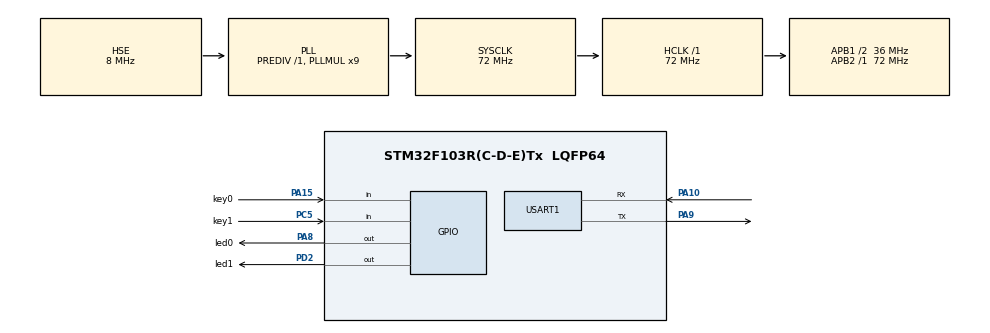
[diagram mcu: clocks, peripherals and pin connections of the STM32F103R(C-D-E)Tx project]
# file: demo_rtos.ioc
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Dma.Request0=USART1_RX
Dma.Request1=USART1_TX
Dma.USART1_RX.0.Direction=DMA_PERIPH_TO_MEMORY
Dma.USART1_RX.0.Instance=DMA1_Channel5
Dma.USART1_RX.0.MemDataAlignment=DMA_MDATAALIGN_BYTE
Dma.USART1_RX.0.MemInc=DMA_MINC_ENABLE
Dma.USART1_RX.0.Mode=DMA_NORMAL
Dma.USART1_RX.0.PeriphDataAlignment=DMA_PDATAALIGN_BYTE
Dma.USART1_RX.0.PeriphInc=DMA_PINC_DISABLE
Dma.USART1_RX.0.Priority=DMA_PRIORITY_LOW
Dma.USART1_TX.1.Direction=DMA_MEMORY_TO_PERIPH
Dma.USART1_TX.1.Instance=DMA1_Channel4
Dma.USART1_TX.1.MemDataAlignment=DMA_MDATAALIGN_BYTE
Dma.USART1_TX.1.MemInc=DMA_MINC_ENABLE
Dma.USART1_TX.1.Mode=DMA_NORMAL
Dma.USART1_TX.1.PeriphDataAlignment=DMA_PDATAALIGN_BYTE
Dma.USART1_TX.1.PeriphInc=DMA_PINC_DISABLE
Dma.USART1_TX.1.Priority=DMA_PRIORITY_LOW
FREERTOS.INCLUDE_eTaskGetState=0
FREERTOS.INCLUDE_uxTaskGetStackHighWaterMark=1
FREERTOS.INCLUDE_xQueueGetMutexHolder=1
FREERTOS.Tasks01=led0_on_and_off,24,128,led_task1,Default,NULL,Dynamic,NULL,NULL;led1taskk02,8,128,led_task2,Default,NULL,Dynamic,NULL,NULL
Mcu.Family=STM32F1
Mcu.Name=STM32F103R(C-D-E)Tx
Mcu.Package=LQFP64
NVIC.DMA1_Channel4_IRQn=true\:5\:0\:false\:false\:true\:true\:false\:true\:true
NVIC.DMA1_Channel5_IRQn=true\:5\:0\:false\:false\:true\:true\:false\:true\:true
NVIC.PriorityGroup=NVIC_PRIORITYGROUP_4
NVIC.TIM2_IRQn=true\:15\:0\:false\:false\:true\:false\:false\:true\:true
NVIC.TimeBase=TIM2_IRQn
NVIC.TimeBaseIP=TIM2
NVIC.USART1_IRQn=true\:5\:0\:true\:false\:true\:true\:true\:true\:true
PA10.Mode=Asynchronous
PA10.Signal=USART1_RX
PA13.Mode=Serial_Wire
PA13.Signal=SYS_JTMS-SWDIO
PA14.Mode=Serial_Wire
PA14.Signal=SYS_JTCK-SWCLK
PA15.GPIO_Label=key0
PA15.GPIO_PuPd=GPIO_NOPULL
PA15.Signal=GPIO_Input
PA8.GPIO_Label=led0
PA8.GPIO_PuPd=GPIO_PULLUP
PA8.GPIO_Speed=GPIO_SPEED_FREQ_MEDIUM
PA8.Signal=GPIO_Output
PA9.Mode=Asynchronous
PA9.Signal=USART1_TX
PC14-OSC32_IN.Mode=LSE-External-Oscillator
PC14-OSC32_IN.Signal=RCC_OSC32_IN
PC15-OSC32_OUT.Mode=LSE-External-Oscillator
PC15-OSC32_OUT.Signal=RCC_OSC32_OUT
PC5.GPIO_Label=key1
PC5.GPIO_PuPd=GPIO_NOPULL
PC5.Signal=GPIO_Input
PD0-OSC_IN.Mode=HSE-External-Oscillator
PD0-OSC_IN.Signal=RCC_OSC_IN
PD1-OSC_OUT.Mode=HSE-External-Oscillator
PD1-OSC_OUT.Signal=RCC_OSC_OUT
PD2.GPIO_Label=led1
PD2.GPIO_PuPd=GPIO_PULLUP
PD2.GPIO_Speed=GPIO_SPEED_FREQ_MEDIUM
PD2.Signal=GPIO_Output
ProjectManager.HeapSize=0x200
ProjectManager.StackSize=0x400
ProjectManager.TargetToolchain=MDK-ARM V5.32
RCC.AHBFreq_Value=72000000
RCC.APB1CLKDivider=RCC_HCLK_DIV2
RCC.APB1Freq_Value=36000000
RCC.APB1TimFreq_Value=72000000
RCC.APB2Freq_Value=72000000
RCC.APB2TimFreq_Value=72000000
RCC.HCLKFreq_Value=72000000
RCC.PLLMUL=RCC_PLL_MUL9
RCC.PLLSourceVirtual=RCC_PLLSOURCE_HSE
RCC.SYSCLKFreq_VALUE=72000000
RCC.SYSCLKSource=RCC_SYSCLKSOURCE_PLLCLK
RCC.USBFreq_Value=72000000
USART1.VirtualMode=VM_ASYNC
VP_FREERTOS_VS_CMSIS_V2.Mode=CMSIS_V2
VP_SYS_VS_tim2.Mode=TIM2
board=custom

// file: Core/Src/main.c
/* USER CODE BEGIN Header */
/**
  ******************************************************************************
  * @file           : main.c
  * @brief          : Main program body
  ******************************************************************************
  * @attention
  *
  * Copyright (c) 2023 STMicroelectronics.
  * All rights reserved.
  *
  * This software is licensed under terms that can be found in the LICENSE file
  * in the root directory of this software component.
  * If no LICENSE file comes with this software, it is provided AS-IS.
  *
  ******************************************************************************
  */
/* USER CODE END Header */
#include "main.h"
#include "cmsis_os.h"
#include "dma.h"
#include "usart.h"
#include "gpio.h"

void SystemClock_Config(void);
void MX_FREERTOS_Init(void);

int main(void)
{

  /* MCU Configuration--------------------------------------------------------*/

  /* Reset of all peripherals, Initializes the Flash interface and the Systick. */
  HAL_Init();

  /* Configure the system clock */
  SystemClock_Config();

  /* Initialize all configured peripherals */
  MX_GPIO_Init();
  MX_DMA_Init();
  MX_USART1_UART_Init();

  /* Init scheduler */
  osKernelInitialize();  /* Call init function for freertos objects (in freertos.c) */
  MX_FREERTOS_Init();

  /* Start scheduler */
  osKernelStart();

  /* We should never get here as control is now taken by the scheduler */
  /* Infinite loop */
  while (1)
  {

  }
}

void SystemClock_Config(void)
{
  RCC_OscInitTypeDef RCC_OscInitStruct = {0};
  RCC_ClkInitTypeDef RCC_ClkInitStruct = {0};

  /** Initializes the RCC Oscillators according to the specified parameters
  * in the RCC_OscInitTypeDef structure.
  */
  RCC_OscInitStruct.OscillatorType = RCC_OSCILLATORTYPE_HSE;
  RCC_OscInitStruct.HSEState = RCC_HSE_ON;
  RCC_OscInitStruct.HSEPredivValue = RCC_HSE_PREDIV_DIV1;
  RCC_OscInitStruct.HSIState = RCC_HSI_ON;
  RCC_OscInitStruct.PLL.PLLState = RCC_PLL_ON;
  RCC_OscInitStruct.PLL.PLLSource = RCC_PLLSOURCE_HSE;
  RCC_OscInitStruct.PLL.PLLMUL = RCC_PLL_MUL9;
  if (HAL_RCC_OscConfig(&RCC_OscInitStruct) != HAL_OK)
  {
    Error_Handler();
  }

  /** Initializes the CPU, AHB and APB buses clocks
  */
  RCC_ClkInitStruct.ClockType = RCC_CLOCKTYPE_HCLK|RCC_CLOCKTYPE_SYSCLK
                              |RCC_CLOCKTYPE_PCLK1|RCC_CLOCKTYPE_PCLK2;
  RCC_ClkInitStruct.SYSCLKSource = RCC_SYSCLKSOURCE_PLLCLK;
  RCC_ClkInitStruct.AHBCLKDivider = RCC_SYSCLK_DIV1;
  RCC_ClkInitStruct.APB1CLKDivider = RCC_HCLK_DIV2;
  RCC_ClkInitStruct.APB2CLKDivider = RCC_HCLK_DIV1;

  if (HAL_RCC_ClockConfig(&RCC_ClkInitStruct, FLASH_LATENCY_2) != HAL_OK)
  {
    Error_Handler();
  }
}

void HAL_TIM_PeriodElapsedCallback(TIM_HandleTypeDef *htim)
{
  if (htim->Instance == TIM2) {
    HAL_IncTick();
  }
}

void Error_Handler(void)
{
  __disable_irq();
  while (1)
  {
  }
}

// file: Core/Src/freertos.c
/* USER CODE BEGIN Header */
/**
  ******************************************************************************
  * File Name          : freertos.c
  * Description        : Code for freertos applications
  ******************************************************************************
  * @attention
  *
  * Copyright (c) 2023 STMicroelectronics.
  * All rights reserved.
  *
  * This software is licensed under terms that can be found in the LICENSE file
  * in the root directory of this software component.
  * If no LICENSE file comes with this software, it is provided AS-IS.
  *
  ******************************************************************************
  */
/* USER CODE END Header */

#include "FreeRTOS.h"
#include "task.h"
#include "main.h"
#include "cmsis_os.h"

/* USER CODE BEGIN Includes */
#include "key_led.h"
/* USER CODE END Includes */

/* Definitions for led0_on_and_off */
osThreadId_t led0_on_and_offHandle;
const osThreadAttr_t led0_on_and_off_attributes = {
  .name = "led0_on_and_off",
  .stack_size = 128 * 4,
  .priority = (osPriority_t) osPriorityNormal,
};
/* Definitions for led1taskk02 */
osThreadId_t led1taskk02Handle;
const osThreadAttr_t led1taskk02_attributes = {
  .name = "led1taskk02",
  .stack_size = 128 * 4,
  .priority = (osPriority_t) osPriorityLow,
};

void led_task1(void *argument);
void led_task2(void *argument);

void MX_FREERTOS_Init(void); /* (MISRA C 2004 rule 8.1) */

void MX_FREERTOS_Init(void) {

  /* Create the thread(s) */
  /* creation of led0_on_and_off */
  led0_on_and_offHandle = osThreadNew(led_task1, NULL, &led0_on_and_off_attributes);

  /* creation of led1taskk02 */
  led1taskk02Handle = osThreadNew(led_task2, NULL, &led1taskk02_attributes);

}

void led_task1(void *argument)
{
  /* USER CODE BEGIN led_task1 */
  /* Infinite loop */
  for(;;)
  {
		led0_on();
		HAL_Delay(500);
		led0_off();
		HAL_Delay(500);

    osDelay(1);
  }
  /* USER CODE END led_task1 */
}

void led_task2(void *argument)
{
  /* USER CODE BEGIN led_task2 */
  /* Infinite loop */
  for(;;)
  {
		led1_on();
		HAL_Delay(1000);
		led1_off();
		HAL_Delay(1000);
    osDelay(1);
  }
  /* USER CODE END led_task2 */
}
